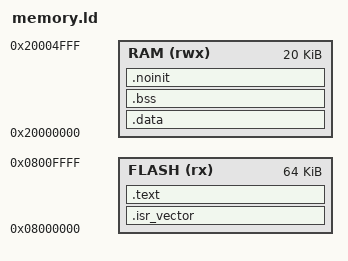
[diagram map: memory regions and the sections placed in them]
ENTRY(Reset_Handler)

MEMORY
{
    FLASH (rx)  : ORIGIN = 0x08000000, LENGTH = 64K
    RAM   (rwx) : ORIGIN = 0x20000000, LENGTH = 20K
}

_estack = ORIGIN(RAM) + LENGTH(RAM);
_Min_Main_Stack_Size = 0x800;

SECTIONS
{
    .isr_vector :
    {
        . = ALIGN(256);
        KEEP(*(.isr_vector))
        . = ALIGN(4);
    } > FLASH

    .text :
    {
        . = ALIGN(4);
        *(.text*)
        *(.rodata*)
        *(.glue_7*)
        *(.glue_7t*)
        . = ALIGN(4);
        _etext = .;
    } > FLASH

    .data : AT(_etext)
    {
        . = ALIGN(4);
        _sdata = .;
        *(.data*)
        . = ALIGN(4);
        _edata = .;
    } > RAM
    _sidata = LOADADDR(.data);

    .bss (NOLOAD) :
    {
        . = ALIGN(8);
        _sbss = .;
        *(.bss*)
        *(COMMON)
        . = ALIGN(8);
        _ebss = .;
    } > RAM

    .noinit (NOLOAD) :
    {
        . = ALIGN(8);
        *(.noinit*)
        . = ALIGN(8);
    } > RAM

    _end = .;
    _sstack = _estack - _Min_Main_Stack_Size;

    /DISCARD/ :
    {
        *(.comment*)
        *(.note*)
        *(.eh_frame*)
        *(.ARM.exidx*)
        *(.ARM.extab*)
    }
}

ASSERT(_end <= _sstack, "RAM overflow: static data overlaps the main exception stack")
